# VIMS register map
Vendor: Texas Instruments
Peripheral module from a debugger description file (folder CC23x0R2).
Registers are 32-bit, access per field, reset 0x7 unless marked. A register's access mark holds for its fields unless they carry their own. Offsets are as the file gives them; lines under a group give offsets from that group; [hi:lo] are bit positions; {n}, {i} and the like mark numbered series; 'fields as' and 'values as' point back to an identical list; <NAME> marks a mode.

## VIMS — Loki VIMS module toplevel
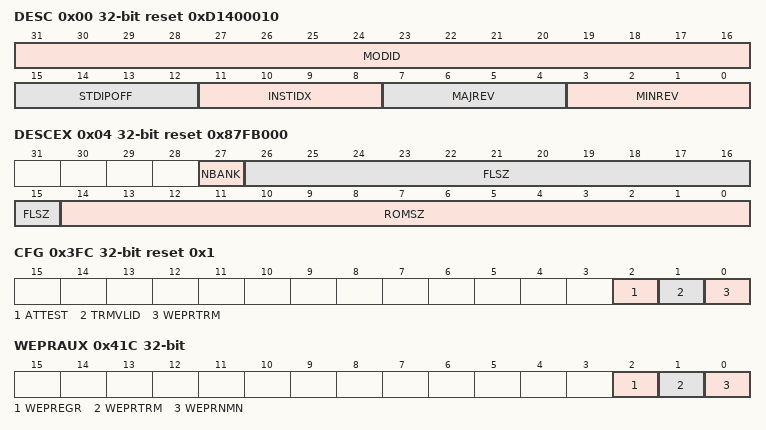
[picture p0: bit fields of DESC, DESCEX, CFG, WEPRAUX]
0x00 DESC ro reset 0xD1400010 — This register identifies the peripheral and its exact version.
  [31:16] MODID — Module identification contains a unique peripheral identification number.
  [15:12] STDIPOFF — Standard IP registers offset. Value 0 indicates Standard IP registers are not present. Any other value between 1 to 15 indicates standard IP registers start from address offset 64 * STDIPOFF from base address.
  [11:8] INSTIDX — Instance Index within the device. This will be a parameter to the RTL for modules that can have multiple instances.
  [7:4] MAJREV — Major revision of IP
  [3:0] MINREV — Minor revision of IP
0x04 DESCEX ro reset 0x87FB000 — This register describes the configuration of VIMS.
  [27] NBANK — Provides the FLASH Bank count
  [26:15] FLSZ — This provides the total FLASH size in Kilo Bytes. The total FLASH size is (FLSZ + 1)KB
  [14:0] ROMSZ — Provides the size of ROM in Bytes.
0x08 FLWS1T — This register is used to specify the number of waitstates necessary for accessing the flash in 1T mode. This register is retained.
  [2:0] VAL rw — Specifies the waitstate value.
    {v}=WS{v} (Wait state value {v}) (v=0..7)
0x0C FLWS2T — This register is used to specify the number of waitstates necessary for accessing the flash in 2T mode. This register is retained.
  fields as FLWS1T
0x18 PTRMC0 rw reset 0x131A0000 — Stores FLASH Pump trim values. This register is retained.
  [31:0] VAL — Flash charge pump trim value.
0x1C B0TRMC1 rw reset 0x0 — This register is used to store flash bank 0 trim value 1. This register is retained.
  [31:0] VAL — Flash bank trim value.
0x20 B0TRMC0 rw reset 0x0 — This register is used to store flash bank 0 trim value 0. This register is retained.
  [31:0] VAL — Flash bank trim value.
0x100 FLBLCK reset 0x0 — This register is used to block user read, write and erase operation to flash. This register is sticky when written with value 1. This register is retained.
  [0] VAL rw — Used to allow or block flash operation.
    1=BLOCK; 0=ALLOW
0x3FC CFG reset 0x1 — This register is used for flash configuration. This register is retained.
  [2] ATTEST rw — This bit is used to enable flash test mode.
  [1] TRMVLID rw — This bit indicates if flash charge pump and bank trim values are valid.
  [0] WEPRTRM rw — This bit is used to write protect flash 1T $amp; 2T waitstate registers, flash charge pump and bank trim registers, TRMVLID and ATTEST configuration registers. This register is sticky when written with value 0.
    1=ALLOW; 0=RESTRICT (Block)
0x400 RDPRMN — Flash main region read protection register upto first 8KB. This register is sticky when written with value 0. This register is retained.
  [2:0] VAL rw — Flash read protection configuration value.
0x404 RDPRNMN reset 0x3F — Flash non main region read protection register for last 512 B. This register is sticky when written with value 0. This register is retained.
  [5:0] VAL rw — Flash read protection configuration value.
0x408 RDPRTRM reset 0x3F — Flash trim region read protection register for last 512 B. This register is sticky when written with value 0. This register is retained.
  [5:0] VAL rw — Flash read protection configuration value.
0x40C RDPREGR reset 0x1 — Flash engr region read protection register. This register is sticky when written with value 0. This register is retained
  [0] VAL rw — Flash read protection configuration value.
0x410 WEPRA rw reset 0xFFFFFFFF — Flash main region write/erase protection for first 32 sectors. Nth bit corresponds to the Nth sector. This register is sticky when written with value 0. This register is retained.
  [31:0] VAL — Flash write/erase protection configuration value.
0x414 WEPRB reset 0xFFF — Flash main region write/erase protection for remaining sectors. Each bit corresponds to 8 sectors. Bit 0 corresponds to sector 32-39, bit 1 corresponds to sector 40-47 and so on. This register is sticky when written with value 0. This register is retained.
  [11:0] VAL rw — Flash write/erase protection configuration value.
0x41C WEPRAUX — Flash Write/Erase protection for Non-Main, TRIM and ENGR Regions. This register is sticky when written with value 0. This register is retained.
  [2] WEPREGR rw — Flash engr region write/erase protection configuration value.
  [1] WEPRTRM rw — Flash trim region write/erase protection configuration value.
  [0] WEPRNMN rw — Flash non main region write/erase protection configuration value.
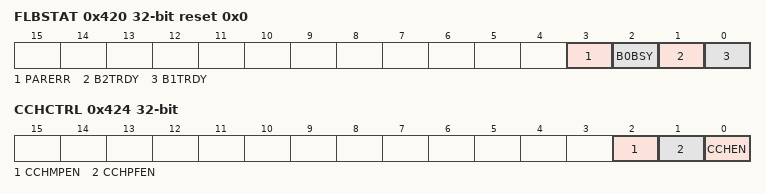
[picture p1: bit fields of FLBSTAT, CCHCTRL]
0x420 FLBSTAT ro reset 0x0 — This register is used to indicate status of flash.
  [3] PARERR — This bit indicates parity error on write/erase $amp; read protection MMRs. This bit is sticky when set to 1 by hardware.
    1=ERROR; 0=NOERROR
  [2] B0BSY — This bit indicates if flash is busy.
    1=BUSY; 0=IDLE
  [1] B2TRDY — This bit indicates if flash is ready in 2T mode.
    1=READY; 0=NOTREADY
  [0] B1TRDY — This bit indicates if flash is ready in 1T mode.
    1=READY; 0=NOTREADY
0x424 CCHCTRL — This register is used for enabling cache, prefetch $amp;amp; micropredictor units. This register is retained
  [all] fields
    1=ENABLE; 0=DISABLE
  [2] CCHMPEN rw — This bit is used to enable the micropredictor unit.
  [1] CCHPFEN rw — This bit is used to enable the prefetch unit.
  [0] CCHEN rw — This bit is used to enable the cache.
0x800 DTB reset 0x0 — Digital test bus mux selection
  [3:0] SEL rw — DTB MUX select pin value
    {v}=GRP{v} (Selects test group {v}) (v=1..15); 0=DISABLE (DTB output from peripheral is 0x0.)
